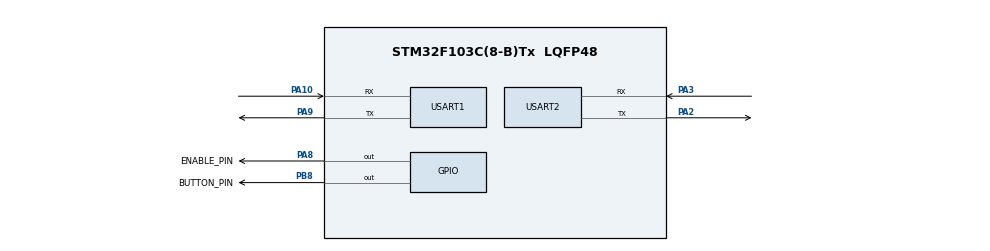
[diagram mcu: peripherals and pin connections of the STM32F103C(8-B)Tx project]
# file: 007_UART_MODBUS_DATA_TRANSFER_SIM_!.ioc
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Dma.Request0=USART1_RX
Dma.Request1=USART1_TX
Dma.Request2=USART2_RX
Dma.Request3=USART2_TX
Dma.USART1_RX.0.Direction=DMA_PERIPH_TO_MEMORY
Dma.USART1_RX.0.Instance=DMA1_Channel5
Dma.USART1_RX.0.MemDataAlignment=DMA_MDATAALIGN_BYTE
Dma.USART1_RX.0.MemInc=DMA_MINC_ENABLE
Dma.USART1_RX.0.Mode=DMA_CIRCULAR
Dma.USART1_RX.0.PeriphDataAlignment=DMA_PDATAALIGN_BYTE
Dma.USART1_RX.0.PeriphInc=DMA_PINC_DISABLE
Dma.USART1_RX.0.Priority=DMA_PRIORITY_LOW
Dma.USART1_TX.1.Direction=DMA_MEMORY_TO_PERIPH
Dma.USART1_TX.1.Instance=DMA1_Channel4
Dma.USART1_TX.1.MemDataAlignment=DMA_MDATAALIGN_BYTE
Dma.USART1_TX.1.MemInc=DMA_MINC_ENABLE
Dma.USART1_TX.1.Mode=DMA_CIRCULAR
Dma.USART1_TX.1.PeriphDataAlignment=DMA_PDATAALIGN_BYTE
Dma.USART1_TX.1.PeriphInc=DMA_PINC_DISABLE
Dma.USART1_TX.1.Priority=DMA_PRIORITY_LOW
Dma.USART2_RX.2.Direction=DMA_PERIPH_TO_MEMORY
Dma.USART2_RX.2.Instance=DMA1_Channel6
Dma.USART2_RX.2.MemDataAlignment=DMA_MDATAALIGN_BYTE
Dma.USART2_RX.2.MemInc=DMA_MINC_ENABLE
Dma.USART2_RX.2.Mode=DMA_CIRCULAR
Dma.USART2_RX.2.PeriphDataAlignment=DMA_PDATAALIGN_BYTE
Dma.USART2_RX.2.PeriphInc=DMA_PINC_DISABLE
Dma.USART2_RX.2.Priority=DMA_PRIORITY_LOW
Dma.USART2_TX.3.Direction=DMA_MEMORY_TO_PERIPH
Dma.USART2_TX.3.Instance=DMA1_Channel7
Dma.USART2_TX.3.MemDataAlignment=DMA_MDATAALIGN_BYTE
Dma.USART2_TX.3.MemInc=DMA_MINC_ENABLE
Dma.USART2_TX.3.Mode=DMA_CIRCULAR
Dma.USART2_TX.3.PeriphDataAlignment=DMA_PDATAALIGN_BYTE
Dma.USART2_TX.3.PeriphInc=DMA_PINC_DISABLE
Dma.USART2_TX.3.Priority=DMA_PRIORITY_LOW
Mcu.Family=STM32F1
Mcu.Name=STM32F103C(8-B)Tx
Mcu.Package=LQFP48
NVIC.DMA1_Channel4_IRQn=true\:0\:0\:false\:false\:true\:false\:true\:true
NVIC.DMA1_Channel5_IRQn=true\:0\:0\:false\:false\:true\:false\:true\:true
NVIC.DMA1_Channel6_IRQn=true\:0\:0\:false\:false\:true\:false\:true\:true
NVIC.DMA1_Channel7_IRQn=true\:0\:0\:false\:false\:true\:false\:true\:true
NVIC.PriorityGroup=NVIC_PRIORITYGROUP_4
NVIC.USART1_IRQn=true\:0\:0\:false\:false\:true\:true\:true\:true
PA10.Mode=Asynchronous
PA10.Signal=USART1_RX
PA13.Mode=Serial_Wire
PA13.Signal=SYS_JTMS-SWDIO
PA14.Mode=Serial_Wire
PA14.Signal=SYS_JTCK-SWCLK
PA2.Mode=Asynchronous
PA2.Signal=USART2_TX
PA3.Mode=Asynchronous
PA3.Signal=USART2_RX
PA8.GPIO_Label=ENABLE_PIN
PA8.Signal=GPIO_Output
PA9.Mode=Asynchronous
PA9.Signal=USART1_TX
PB8.GPIO_Label=BUTTON_PIN
PB8.Signal=GPIO_Output
PC14-OSC32_IN.Mode=LSE-External-Oscillator
PC14-OSC32_IN.Signal=RCC_OSC32_IN
PC15-OSC32_OUT.Mode=LSE-External-Oscillator
PC15-OSC32_OUT.Signal=RCC_OSC32_OUT
PD0-OSC_IN.Mode=HSE-External-Oscillator
PD0-OSC_IN.Signal=RCC_OSC_IN
PD1-OSC_OUT.Mode=HSE-External-Oscillator
PD1-OSC_OUT.Signal=RCC_OSC_OUT
ProjectManager.HeapSize=0x200
ProjectManager.StackSize=0x400
ProjectManager.TargetToolchain=STM32CubeIDE
RCC.APB1Freq_Value=8000000
RCC.APB2Freq_Value=8000000
USART1.VirtualMode=VM_ASYNC
USART2.VirtualMode=VM_ASYNC
board=custom

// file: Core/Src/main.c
/* USER CODE BEGIN Header */
/**
  ******************************************************************************
  * @file           : main.c
  * @brief          : Main program body
  ******************************************************************************
  * @attention
  *
  * Copyright (c) 2024 STMicroelectronics.
  * All rights reserved.
  *
  * This software is licensed under terms that can be found in the LICENSE file
  * in the root directory of this software component.
  * If no LICENSE file comes with this software, it is provided AS-IS.
  *
  ******************************************************************************
  */
/* USER CODE END Header */
#include "main.h"
#include "string.h"

/* USER CODE BEGIN PD */
#define SLAVEADRESS 0x01
#define PB8COILLOW 0x00
#define PB8COILHIGH 0x01
#define CRCLOW 0xE1
#define CRCHIGH 0xDD

/* USER CODE END PD */

UART_HandleTypeDef huart1;
UART_HandleTypeDef huart2;
DMA_HandleTypeDef hdma_usart1_rx;
DMA_HandleTypeDef hdma_usart1_tx;
DMA_HandleTypeDef hdma_usart2_rx;
DMA_HandleTypeDef hdma_usart2_tx;

void SystemClock_Config(void);
static void MX_GPIO_Init(void);
static void MX_DMA_Init(void);
static void MX_USART1_UART_Init(void);
static void MX_USART2_UART_Init(void);

int main(void)
{

  /* MCU Configuration--------------------------------------------------------*/

  /* Reset of all peripherals, Initializes the Flash interface and the Systick. */
  HAL_Init();

  /* Configure the system clock */
  SystemClock_Config();

  /* Initialize all configured peripherals */
  MX_GPIO_Init();
  MX_DMA_Init();
  MX_USART1_UART_Init();
  MX_USART2_UART_Init();
  /* USER CODE BEGIN 2 */

  uint8_t BUFFER[] = {SLAVEADRESS, 0x05, PB8COILLOW, PB8COILHIGH, 0xFF, CRCLOW,CRCHIGH };

  /* USER CODE END 2 */

  /* Infinite loop */
  while (1)
  {

    /* USER CODE BEGIN 3 */
	  if(BUTTON_PIN_Pin==SET){	//EGER BUTON ON ISE VERIYI GONDER.
		  HAL_UART_Transmit(&huart1, BUFFER, sizeof(BUFFER), 1000);
	  }

	  else{ //DIGER DURUMDA HATA MESAJI GONDER.
		  char HATA[50];
		  sprintf(HATA,"HATA KODU: %d",404);
		  HAL_UART_Transmit(&huart1, (uint8_t*)HATA, strlen(HATA), HAL_MAX_DELAY);

	  }

  }
  /* USER CODE END 3 */
}

void SystemClock_Config(void)
{
  RCC_OscInitTypeDef RCC_OscInitStruct = {0};
  RCC_ClkInitTypeDef RCC_ClkInitStruct = {0};

  /** Initializes the RCC Oscillators according to the specified parameters
  * in the RCC_OscInitTypeDef structure.
  */
  RCC_OscInitStruct.OscillatorType = RCC_OSCILLATORTYPE_HSI;
  RCC_OscInitStruct.HSIState = RCC_HSI_ON;
  RCC_OscInitStruct.HSICalibrationValue = RCC_HSICALIBRATION_DEFAULT;
  RCC_OscInitStruct.PLL.PLLState = RCC_PLL_NONE;
  if (HAL_RCC_OscConfig(&RCC_OscInitStruct) != HAL_OK)
  {
    Error_Handler();
  }

  /** Initializes the CPU, AHB and APB buses clocks
  */
  RCC_ClkInitStruct.ClockType = RCC_CLOCKTYPE_HCLK|RCC_CLOCKTYPE_SYSCLK
                              |RCC_CLOCKTYPE_PCLK1|RCC_CLOCKTYPE_PCLK2;
  RCC_ClkInitStruct.SYSCLKSource = RCC_SYSCLKSOURCE_HSI;
  RCC_ClkInitStruct.AHBCLKDivider = RCC_SYSCLK_DIV1;
  RCC_ClkInitStruct.APB1CLKDivider = RCC_HCLK_DIV1;
  RCC_ClkInitStruct.APB2CLKDivider = RCC_HCLK_DIV1;

  if (HAL_RCC_ClockConfig(&RCC_ClkInitStruct, FLASH_LATENCY_0) != HAL_OK)
  {
    Error_Handler();
  }
}

static void MX_USART1_UART_Init(void)
{

  huart1.Instance = USART1;
  huart1.Init.BaudRate = 115200;
  huart1.Init.WordLength = UART_WORDLENGTH_8B;
  huart1.Init.StopBits = UART_STOPBITS_1;
  huart1.Init.Parity = UART_PARITY_NONE;
  huart1.Init.Mode = UART_MODE_TX_RX;
  huart1.Init.HwFlowCtl = UART_HWCONTROL_NONE;
  huart1.Init.OverSampling = UART_OVERSAMPLING_16;
  if (HAL_UART_Init(&huart1) != HAL_OK)
  {
    Error_Handler();
  }

}

static void MX_USART2_UART_Init(void)
{

  huart2.Instance = USART2;
  huart2.Init.BaudRate = 115200;
  huart2.Init.WordLength = UART_WORDLENGTH_8B;
  huart2.Init.StopBits = UART_STOPBITS_1;
  huart2.Init.Parity = UART_PARITY_NONE;
  huart2.Init.Mode = UART_MODE_TX_RX;
  huart2.Init.HwFlowCtl = UART_HWCONTROL_NONE;
  huart2.Init.OverSampling = UART_OVERSAMPLING_16;
  if (HAL_UART_Init(&huart2) != HAL_OK)
  {
    Error_Handler();
  }

}

static void MX_DMA_Init(void)
{

  /* DMA controller clock enable */
  __HAL_RCC_DMA1_CLK_ENABLE();

  /* DMA interrupt init */
  /* DMA1_Channel4_IRQn interrupt configuration */
  HAL_NVIC_SetPriority(DMA1_Channel4_IRQn, 0, 0);
  HAL_NVIC_EnableIRQ(DMA1_Channel4_IRQn);
  /* DMA1_Channel5_IRQn interrupt configuration */
  HAL_NVIC_SetPriority(DMA1_Channel5_IRQn, 0, 0);
  HAL_NVIC_EnableIRQ(DMA1_Channel5_IRQn);
  /* DMA1_Channel6_IRQn interrupt configuration */
  HAL_NVIC_SetPriority(DMA1_Channel6_IRQn, 0, 0);
  HAL_NVIC_EnableIRQ(DMA1_Channel6_IRQn);
  /* DMA1_Channel7_IRQn interrupt configuration */
  HAL_NVIC_SetPriority(DMA1_Channel7_IRQn, 0, 0);
  HAL_NVIC_EnableIRQ(DMA1_Channel7_IRQn);

}

static void MX_GPIO_Init(void)
{
  GPIO_InitTypeDef GPIO_InitStruct = {0};

  /* GPIO Ports Clock Enable */
  __HAL_RCC_GPIOC_CLK_ENABLE();
  __HAL_RCC_GPIOD_CLK_ENABLE();
  __HAL_RCC_GPIOA_CLK_ENABLE();
  __HAL_RCC_GPIOB_CLK_ENABLE();

  /*Configure GPIO pin Output Level */
  HAL_GPIO_WritePin(ENABLE_PIN_GPIO_Port, ENABLE_PIN_Pin, GPIO_PIN_RESET);

  /*Configure GPIO pin Output Level */
  HAL_GPIO_WritePin(BUTTON_PIN_GPIO_Port, BUTTON_PIN_Pin, GPIO_PIN_RESET);

  /*Configure GPIO pin : ENABLE_PIN_Pin */
  GPIO_InitStruct.Pin = ENABLE_PIN_Pin;
  GPIO_InitStruct.Mode = GPIO_MODE_OUTPUT_PP;
  GPIO_InitStruct.Pull = GPIO_NOPULL;
  GPIO_InitStruct.Speed = GPIO_SPEED_FREQ_LOW;
  HAL_GPIO_Init(ENABLE_PIN_GPIO_Port, &GPIO_InitStruct);

  /*Configure GPIO pin : BUTTON_PIN_Pin */
  GPIO_InitStruct.Pin = BUTTON_PIN_Pin;
  GPIO_InitStruct.Mode = GPIO_MODE_OUTPUT_PP;
  GPIO_InitStruct.Pull = GPIO_NOPULL;
  GPIO_InitStruct.Speed = GPIO_SPEED_FREQ_LOW;
  HAL_GPIO_Init(BUTTON_PIN_GPIO_Port, &GPIO_InitStruct);

}

void Error_Handler(void)
{
  __disable_irq();
  while (1)
  {
  }
}
